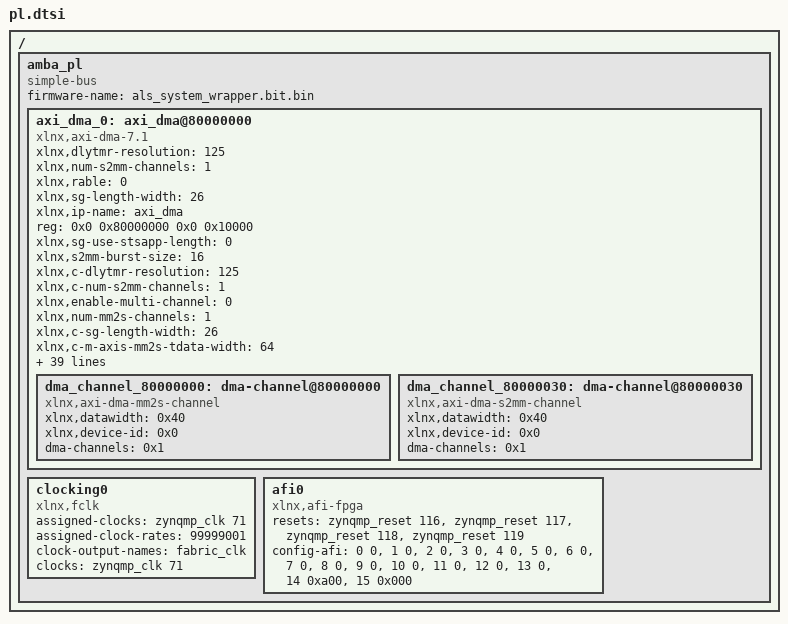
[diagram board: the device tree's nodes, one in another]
/ {
	amba_pl: amba_pl {
		ranges;
		compatible = "simple-bus";
		#address-cells = <2>;
		#size-cells = <2>;
		firmware-name = "als_system_wrapper.bit.bin";
		axi_dma_0: axi_dma@80000000 {
			xlnx,dlytmr-resolution = <125>;
			xlnx,num-s2mm-channels = <1>;
			xlnx,rable = <0>;
			xlnx,sg-length-width = <26>;
			xlnx,ip-name = "axi_dma";
			reg = <0x0 0x80000000 0x0 0x10000>;
			xlnx,sg-use-stsapp-length = <0>;
			xlnx,s2mm-burst-size = <16>;
			xlnx,c-dlytmr-resolution = <125>;
			xlnx,c-num-s2mm-channels = <1>;
			xlnx,enable-multi-channel = <0>;
			xlnx,num-mm2s-channels = <1>;
			xlnx,c-sg-length-width = <26>;
			compatible = "xlnx,axi-dma-7.1" , "xlnx,axi-dma-1.00.a";
			xlnx,c-m-axis-mm2s-tdata-width = <64>;
			xlnx,c-sg-use-stsapp-length = <0>;
			xlnx,c-s2mm-burst-size = <16>;
			xlnx,mm2s-burst-size = <8>;
			xlnx,c-enable-multi-channel = <0>;
			xlnx,c-num-mm2s-channels = <1>;
			xlnx,include-s2mm-dre = <0>;
			xlnx,include-sg;
			xlnx,c-mm2s-burst-size = <8>;
			status = "okay";
			xlnx,c-include-s2mm-dre = <0>;
			xlnx,include-mm2s-dre = <0>;
			xlnx,name = "axi_dma_0";
			xlnx,c-include-sg = <1>;
			xlnx,c-m-axi-s2mm-data-width = <64>;
			xlnx,include-s2mm-sf = <1>;
			xlnx,c-include-mm2s-dre = <0>;
			xlnx,include-s2mm = <1>;
			clocks = <&zynqmp_clk 71>, <&zynqmp_clk 71>, <&zynqmp_clk 71>, <&zynqmp_clk 71>;
			xlnx,addrwidth = <0x40>;
			xlnx,c-m-axi-mm2s-data-width = <64>;
			xlnx,edk-iptype = "PERIPHERAL";
			xlnx,c-include-s2mm-sf = <1>;
			xlnx,include-mm2s-sf = <1>;
			clock-names = "m_axi_mm2s_aclk" , "m_axi_s2mm_aclk" , "m_axi_sg_aclk" , "s_axi_lite_aclk";
			xlnx,c-include-s2mm = <1>;
			xlnx,c-addr-width = <64>;
			xlnx,c-single-interface = <0>;
			xlnx,include-mm2s = <1>;
			xlnx,c-s-axis-s2mm-tdata-width = <64>;
			xlnx,s2mm-data-width = <0x40>;
			xlnx,c-include-mm2s-sf = <1>;
			xlnx,prmry-is-aclk-async = <0>;
			xlnx,c-include-mm2s = <1>;
			xlnx,increase-throughput = <0>;
			xlnx,micro-dma = <0>;
			xlnx,mm2s-data-width = <0x40>;
			xlnx,c-prmry-is-aclk-async = <0>;
			xlnx,c-sg-include-stscntrl-strm = <0>;
			xlnx,c-increase-throughput = <0>;
			xlnx,c-micro-dma = <0>;
			dma_channel_80000000: dma-channel@80000000 {
				xlnx,datawidth = <0x40>;
				xlnx,device-id = <0x0>;
				compatible = "xlnx,axi-dma-mm2s-channel";
				dma-channels = <0x1>;
			};
			dma_channel_80000030: dma-channel@80000030 {
				xlnx,datawidth = <0x40>;
				xlnx,device-id = <0x0>;
				compatible = "xlnx,axi-dma-s2mm-channel";
				dma-channels = <0x1>;
			};
		};
		clocking0: clocking0 {
			compatible = "xlnx,fclk";
			assigned-clocks = <&zynqmp_clk 71>;
			assigned-clock-rates = <99999001>;
			#clock-cells = <0>;
			clock-output-names = "fabric_clk";
			clocks = <&zynqmp_clk 71>;
		};
		afi0: afi0 {
			status = "okay";
			compatible = "xlnx,afi-fpga";
			resets = <&zynqmp_reset 116>, <&zynqmp_reset 117>, <&zynqmp_reset 118>, <&zynqmp_reset 119>;
			config-afi = < 0 0>, <1 0>, <2 0>, <3 0>, <4 0>, <5 0>, <6 0>, <7 0>, <8 0>, <9 0>, <10 0>, <11 0>, <12 0>, <13 0>, <14 0xa00>, <15 0x000>;
		};
	};
};
